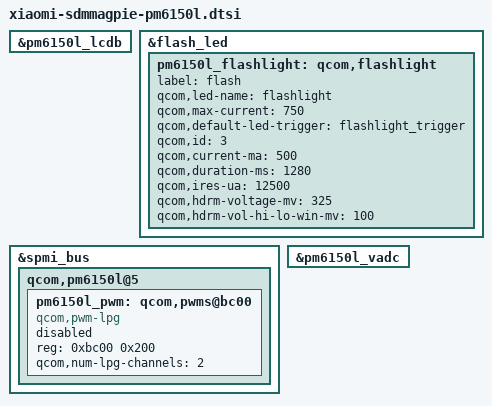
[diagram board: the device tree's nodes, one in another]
&pm6150l_lcdb {
    /delete-property/ qcom,voltage-step-ramp;
};

&flash_led {
    pm6150l_flashlight: qcom,flashlight {
    label = "flash";
    qcom,led-name = "flashlight";
    qcom,max-current = <750>;
    qcom,default-led-trigger = "flashlight_trigger";
    qcom,id = <3>;
    qcom,current-ma = <500>;
    qcom,duration-ms = <1280>;
    qcom,ires-ua = <12500>;
    qcom,hdrm-voltage-mv = <325>;
    qcom,hdrm-vol-hi-lo-win-mv = <100>;
    };
};

&spmi_bus {
    qcom,pm6150l@5 {
        pm6150l_pwm: qcom,pwms@bc00 {
            compatible = "qcom,pwm-lpg";
            reg = <0xbc00 0x200>;
            reg-names = "lpg-base";
            #pwm-cells = <2>;
            qcom,num-lpg-channels = <2>;
            status = "disabled";
        };
    };
};

&pm6150l_vadc {
    /delete-property/ pinctrl-names;
    /delete-property/ pinctrl-0;
};
